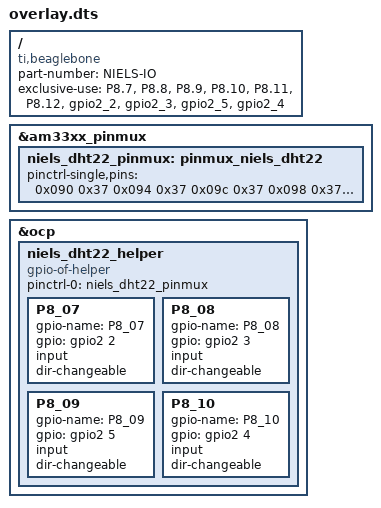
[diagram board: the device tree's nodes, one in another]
/dts-v1/;
/plugin/;

/ {
	compatible = "ti,beaglebone", "ti,beaglebone-black";

	part-number = "NIELS-IO";

	exclusive-use =
		"P8.7",
		"P8.8",
		"P8.9",
		"P8.10",
		"P8.11",
		"P8.12",
		"gpio2_2",
		"gpio2_3",
		"gpio2_5",
		"gpio2_4";

	fragment@0 {
		target = <&am33xx_pinmux>;
		__overlay__ {
			niels_dht22_pinmux: pinmux_niels_dht22 {
				pinctrl-single,pins = <
					0x090 0x37 // P8_07 (TIMER4): mode 7 (gpio), pull up, Rx enabled
					0x094 0x37 // P8_08 (TIMER7): mode 7 (gpio), pull up, Rx enabled
					0x09c 0x37 // P8_09 (TIMER5): mode 7 (gpio), pull up, Rx enabled
					0x098 0x37 // P8_10 (TIMER6): mode 7 (gpio), pull up, Rx enabled
					0x034 0x0e // P8_11 (GPIO1_13): mode 6 (PRU), no pull
					0x030 0x0e // P8_12 (GPIO1_11): mode 6 (PRU), no pull
				>;
			};
		};
	};

	fragment@1 {
		target = <&ocp>;
		__overlay__ {
			//niels_dht22_pinmux_helper {
			//	compatible = "bone-pinmux-helper";
			//	pinctrl-names = "default";
			//	pinctrl-0 = <&niels_dht22>;
			//	status = "okay";
			//};

			niels_dht22_helper {
				compatible = "gpio-of-helper";
				pinctrl-names = "default";
				pinctrl-0 = <&niels_dht22_pinmux>;
				status = "okay";

				P8_07 {
					gpio-name = "P8_07";
					gpio = <&gpio2 2 0>;
					input;
					dir-changeable;
				};
				P8_08 {
					gpio-name = "P8_08";
					gpio = <&gpio2 3 0>;
					input;
					dir-changeable;
				};
				P8_09 {
					gpio-name = "P8_09";
					gpio = <&gpio2 5 0>;
					input;
					dir-changeable;
				};
				P8_10 {
					gpio-name = "P8_10";
					gpio = <&gpio2 4 0>;
					input;
					dir-changeable;
				};
			};
		};
	};
};
